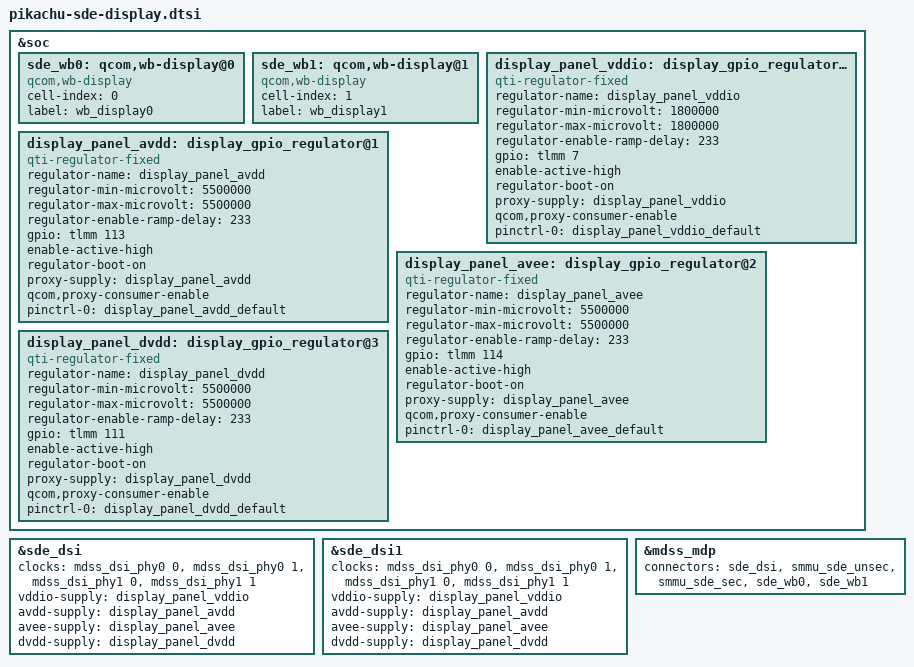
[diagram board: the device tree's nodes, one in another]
// SPDX-License-Identifier: BSD-3-Clause
/*
 * Copyright (c) Qualcomm Technologies, Inc. and/or its subsidiaries.
 */

#include "pikachu-sde.dtsi"
#include "pikachu-sde-display-common.dtsi"

&soc {
	sde_wb0: qcom,wb-display@0 {
		compatible = "qcom,wb-display";
		cell-index = <0>;
		label = "wb_display0";
	};

	sde_wb1: qcom,wb-display@1 {
		compatible = "qcom,wb-display";
		cell-index = <1>;
		label = "wb_display1";
	};

	display_panel_vddio: display_gpio_regulator@0 {
		compatible = "qti-regulator-fixed";
		regulator-name = "display_panel_vddio";
		regulator-min-microvolt = <1800000>;
		regulator-max-microvolt = <1800000>;
		regulator-enable-ramp-delay = <233>;
		gpio = <&tlmm 7 0>;
		enable-active-high;
		regulator-boot-on;
		proxy-supply = <&display_panel_vddio>;
		qcom,proxy-consumer-enable;
		pinctrl-names = "default";
		pinctrl-0 = <&display_panel_vddio_default>;
	};

	display_panel_avdd: display_gpio_regulator@1 {
		compatible = "qti-regulator-fixed";
		regulator-name = "display_panel_avdd";
		regulator-min-microvolt = <5500000>;
		regulator-max-microvolt = <5500000>;
		regulator-enable-ramp-delay = <233>;
		gpio = <&tlmm 113 0>;
		enable-active-high;
		regulator-boot-on;
		proxy-supply = <&display_panel_avdd>;
		qcom,proxy-consumer-enable;
		pinctrl-names = "default";
		pinctrl-0 = <&display_panel_avdd_default>;
	};

	display_panel_avee: display_gpio_regulator@2 {
		compatible = "qti-regulator-fixed";
		regulator-name = "display_panel_avee";
		regulator-min-microvolt = <5500000>;
		regulator-max-microvolt = <5500000>;
		regulator-enable-ramp-delay = <233>;
		gpio = <&tlmm 114 0>;
		enable-active-high;
		regulator-boot-on;
		proxy-supply = <&display_panel_avee>;
		qcom,proxy-consumer-enable;
		pinctrl-names = "default";
		pinctrl-0 = <&display_panel_avee_default>;
	};

	display_panel_dvdd: display_gpio_regulator@3 {
		compatible = "qti-regulator-fixed";
		regulator-name = "display_panel_dvdd";
		regulator-min-microvolt = <5500000>;
		regulator-max-microvolt = <5500000>;
		regulator-enable-ramp-delay = <233>;
		gpio = <&tlmm 111 0>;
		enable-active-high;
		regulator-boot-on;
		proxy-supply = <&display_panel_dvdd>;
		qcom,proxy-consumer-enable;
		pinctrl-names = "default";
		pinctrl-0 = <&display_panel_dvdd_default>;
	};
};

&sde_dsi {
	clocks = <&mdss_dsi_phy0 0>,
		 <&mdss_dsi_phy0 1>,
		 <&mdss_dsi_phy1 0>,
		 <&mdss_dsi_phy1 1>;
		 /*
		  * Currently the dsi clock handles are under the dsi
		  * controller DT node. As soon as the controller probe
		  * finishes, the dispcc sync state can get called before
		  * the dsi_display probe potentially disturbing the clock
		  * votes for cont_splash use case. Hence we are no longer
		  * protected by the component model in this case against the
		  * disp cc sync state getting triggered after the dsi_ctrl
		  * probe. To protect against this incorrect sync state trigger
		  * add this dummy MDP clk vote handle to the dsi_display
		  * DT node. Since the dsi_display driver does not parse
		  * MDP clock nodes, no actual vote shall be added and this
		  * change is done just to satisfy sync state requirements.
		  */
		 //<&dispcc DISP_CC_MDSS_MDP_CLK>;
	clock-names = "pll_byte_clk0", "pll_dsi_clk0",
		      "pll_byte_clk1", "pll_dsi_clk1";
		     // "mdp_core_clk";

	vddio-supply = <&display_panel_vddio>;
	avdd-supply = <&display_panel_avdd>;
	avee-supply = <&display_panel_avee>;
	dvdd-supply = <&display_panel_dvdd>;
};

&sde_dsi1 {
	clocks = <&mdss_dsi_phy0 0>,
		 <&mdss_dsi_phy0 1>,
		 <&mdss_dsi_phy1 0>,
		 <&mdss_dsi_phy1 1>;
		 /*
		  * Currently the dsi clock handles are under the dsi
		  * controller DT node. As soon as the controller probe
		  * finishes, the dispcc sync state can get called before
		  * the dsi_display probe potentially disturbing the clock
		  * votes for cont_splash use case. Hence we are no longer
		  * protected by the component model in this case against the
		  * disp cc sync state getting triggered after the dsi_ctrl
		  * probe. To protect against this incorrect sync state trigger
		  * add this dummy MDP clk vote handle to the dsi_display
		  * DT node. Since the dsi_display driver does not parse
		  * MDP clock nodes, no actual vote shall be added and this
		  * change is done just to satisfy sync state requirements.
		  */
		 //<&dispcc DISP_CC_MDSS_MDP_CLK>;
	clock-names = "pll_byte_clk0", "pll_dsi_clk0",
		      "pll_byte_clk1", "pll_dsi_clk1";
		      //"mdp_core_clk";

	vddio-supply = <&display_panel_vddio>;
	avdd-supply = <&display_panel_avdd>;
	avee-supply = <&display_panel_avee>;
	dvdd-supply = <&display_panel_dvdd>;
};

&mdss_mdp {
	connectors = <&sde_dsi &smmu_sde_unsec &smmu_sde_sec &sde_wb0 &sde_wb1>;
};
